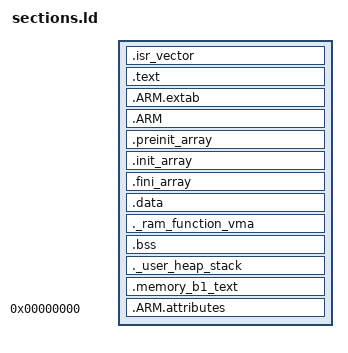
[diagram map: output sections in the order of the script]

/* Define output sections */
SECTIONS
{
  /* The startup code goes first into FLASH */
  .isr_vector :
  {
    . = ALIGN(4);
    KEEP(*(.isr_vector)) /* Startup code */
    . = ALIGN(4);
  } >FLASH

  /* The program code and other data goes into FLASH */
  .text :
  {
    . = ALIGN(4);
    *(.text)           /* .text sections (code) */
    *(.text*)          /* .text* sections (code) */
    *(.rodata)         /* .rodata sections (constants, strings, etc.) */
    *(.rodata*)        /* .rodata* sections (constants, strings, etc.) */
    *(.glue_7)         /* glue arm to thumb code */
    *(.glue_7t)        /* glue thumb to arm code */
    *(.eh_frame)

    KEEP (*(.init))
    KEEP (*(.fini))

    . = ALIGN(4);
    _etext = .;        /* define a global symbols at end of code */
  } >FLASH


   .ARM.extab   : { *(.ARM.extab* .gnu.linkonce.armextab.*) } >FLASH
    .ARM : {
    __exidx_start = .;
      *(.ARM.exidx*)
      __exidx_end = .;
    } >FLASH

  .preinit_array     :
  {
    PROVIDE_HIDDEN (__preinit_array_start = .);
    KEEP (*(.preinit_array*))
    PROVIDE_HIDDEN (__preinit_array_end = .);
  } >FLASH
  .init_array :
  {
    PROVIDE_HIDDEN (__init_array_start = .);
    KEEP (*(SORT(.init_array.*)))
    KEEP (*(.init_array*))
    PROVIDE_HIDDEN (__init_array_end = .);
  } >FLASH
  .fini_array :
  {
    PROVIDE_HIDDEN (__fini_array_start = .);
    KEEP (*(.fini_array*))
    KEEP (*(SORT(.fini_array.*)))
    PROVIDE_HIDDEN (__fini_array_end = .);
  } >FLASH

  /* used by the startup to initialize data */
  _sidata = .;

  /* Initialized data sections goes into RAM, load LMA copy after code */
  .data : AT ( _sidata )
  {
    . = ALIGN(4);
    _sdata = .;        /* create a global symbol at data start */
    *(.data)           /* .data sections */
    *(.data*)          /* .data* sections */

    . = ALIGN(4);
    _edata = .;        /* define a global symbol at data end */
  } >RAM

  /* Section for functions that need to execute out of RAM */
  _ram_function_lma = ( _sidata ) + SIZEOF (.data);
  ._ram_function_vma : AT( _ram_function_lma )
  {
    . = ALIGN(4);
    _s_ram_function_vma = .;
    *(._ram_function) 
    _e_ram_function_vma = .;
    . = ALIGN(4);
  } >RAM

  /* Uninitialized data section */
  . = ALIGN(4);
  .bss :
  {
    /* This is used by the startup in order to initialize the .bss secion */
    _sbss = .;         /* define a global symbol at bss start */
    __bss_start__ = _sbss;
    *(.bss)
    *(.bss*)
    *(COMMON)

    . = ALIGN(4);
    _ebss = .;         /* define a global symbol at bss end */
    __bss_end__ = _ebss;
  } >RAM

  ._user_heap_stack :
  {
    . = ALIGN(4);
    PROVIDE ( end = . );
    PROVIDE ( _end = . );
    
    /* Heap */
    PROVIDE( _user_heap_start_ = . );
    . = . + _Heap_Size;
    . = ALIGN(4);
    PROVIDE( _user_heap_end_ = . );

    /* Check to see if there is enough stack space left */
    PROVIDE( _user_stack_top_ = . );
    . = . + _Min_Stack_Size;
    . = ALIGN(4);
  } >RAM

  /* MEMORY_bank1 section, code must be located here explicitly            */
  /* Example: extern int foo(void) __attribute__ ((section (".mb1text"))); */
  .memory_b1_text :
  {
    *(.mb1text)        /* .mb1text sections (code) */
    *(.mb1text*)       /* .mb1text* sections (code)  */
    *(.mb1rodata)      /* read-only data (constants) */
    *(.mb1rodata*)
  } >MEMORY_B1

  /* Remove information from the standard libraries */
  /DISCARD/ :
  {
    libc.a ( * )
    libm.a ( * )
    libgcc.a ( * )
  }

  .ARM.attributes 0 : { *(.ARM.attributes) }
}
